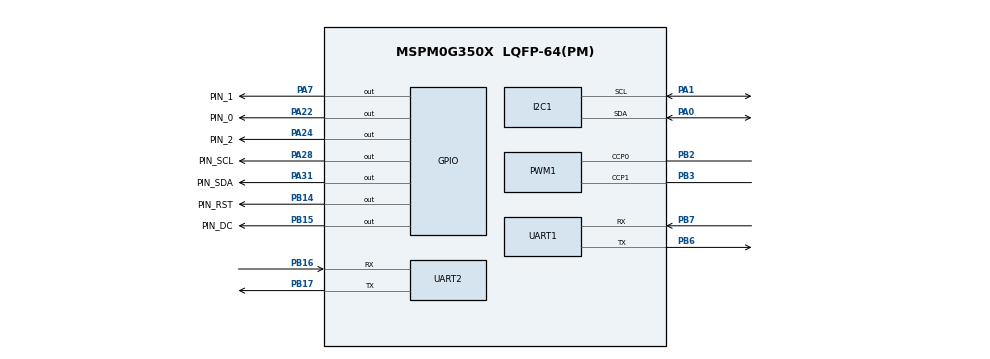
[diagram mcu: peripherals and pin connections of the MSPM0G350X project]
/**
 * These arguments were used when this file was generated. They will be automatically applied on subsequent loads
 * via the GUI or CLI. Run CLI with '--help' for additional information on how to override these arguments.
 * @cliArgs --device "MSPM0G350X" --package "LQFP-64(PM)" --part "Default" --product "mspm0_sdk@2.01.00.03"
 * @versions {"tool":"1.20.0+3587"}
 */

/**
 * Import the modules used in this configuration.
 */
const GPIO    = scripting.addModule("/ti/driverlib/GPIO", {}, false);
const GPIO1   = GPIO.addInstance();
const GPIO2   = GPIO.addInstance();
const GPIO3   = GPIO.addInstance();
const GPIO4   = GPIO.addInstance();
const GPIO5   = GPIO.addInstance();
const GPIO6   = GPIO.addInstance();
const GPIO7   = GPIO.addInstance();
const GPIO8   = GPIO.addInstance();
const GPIO9   = GPIO.addInstance();
const GPIO10  = GPIO.addInstance();
const GPIO11  = GPIO.addInstance();
const ADC12   = scripting.addModule("/ti/driverlib/ADC12", {}, false);
const ADC121  = ADC12.addInstance();
const DMA     = scripting.addModule("/ti/driverlib/DMA", {}, false);
const I2C     = scripting.addModule("/ti/driverlib/I2C", {}, false);
const I2C1    = I2C.addInstance();
const PWM     = scripting.addModule("/ti/driverlib/PWM", {}, false);
const PWM1    = PWM.addInstance();
const SYSCTL  = scripting.addModule("/ti/driverlib/SYSCTL");
const SYSTICK = scripting.addModule("/ti/driverlib/SYSTICK");
const TIMER   = scripting.addModule("/ti/driverlib/TIMER", {}, false);
const TIMER1  = TIMER.addInstance();
const UART    = scripting.addModule("/ti/driverlib/UART", {}, false);
const UART1   = UART.addInstance();
const UART2   = UART.addInstance();

/**
 * Write custom configuration values to the imported modules.
 */
const divider7       = system.clockTree["PLL_PDIV"];
divider7.divideValue = 2;

const divider9       = system.clockTree["UDIV"];
divider9.divideValue = 2;

const multiplier2         = system.clockTree["PLL_QDIV"];
multiplier2.multiplyValue = 5;

const mux8       = system.clockTree["HSCLKMUX"];
mux8.inputSelect = "HSCLKMUX_SYSPLL2X";

GPIO1.$name                         = "OLED_RST";
GPIO1.associatedPins[0].$name       = "PIN_RST";
GPIO1.associatedPins[0].pin.$assign = "PB14";

const Board = scripting.addModule("/ti/driverlib/Board", {}, false);

GPIO2.$name                         = "OLED_DC";
GPIO2.associatedPins[0].$name       = "PIN_DC";
GPIO2.associatedPins[0].pin.$assign = "PB15";

GPIO3.$name                         = "OLED_SCL";
GPIO3.associatedPins[0].$name       = "PIN_SCL";
GPIO3.associatedPins[0].pin.$assign = "PA28";

GPIO4.$name                         = "OLED_SDA";
GPIO4.associatedPins[0].$name       = "PIN_SDA";
GPIO4.associatedPins[0].pin.$assign = "PA31";

GPIO5.$name                          = "LED";
GPIO5.associatedPins[0].$name        = "led_0";
GPIO5.associatedPins[0].initialValue = "SET";
GPIO5.associatedPins[0].assignedPort = "PORTB";
GPIO5.associatedPins[0].assignedPin  = "9";

GPIO6.$name                          = "KEY";
GPIO6.associatedPins[0].$name        = "key_0";
GPIO6.associatedPins[0].direction    = "INPUT";
GPIO6.associatedPins[0].assignedPort = "PORTB";
GPIO6.associatedPins[0].assignedPin  = "8";

GPIO7.$name                          = "AIN";
GPIO7.associatedPins.create(2);
GPIO7.associatedPins[0].$name        = "AIN1";
GPIO7.associatedPins[0].assignedPort = "PORTA";
GPIO7.associatedPins[0].assignedPin  = "13";
GPIO7.associatedPins[1].$name        = "AIN2";
GPIO7.associatedPins[1].assignedPort = "PORTA";
GPIO7.associatedPins[1].assignedPin  = "14";

GPIO8.$name                          = "BIN";
GPIO8.associatedPins.create(2);
GPIO8.associatedPins[0].$name        = "BIN1";
GPIO8.associatedPins[0].assignedPort = "PORTA";
GPIO8.associatedPins[0].assignedPin  = "17";
GPIO8.associatedPins[1].$name        = "BIN2";
GPIO8.associatedPins[1].assignedPort = "PORTA";
GPIO8.associatedPins[1].assignedPin  = "16";

GPIO9.$name                               = "ENCODERA";
GPIO9.associatedPins.create(2);
GPIO9.associatedPins[0].direction         = "INPUT";
GPIO9.associatedPins[0].assignedPort      = "PORTA";
GPIO9.associatedPins[0].assignedPin       = "25";
GPIO9.associatedPins[0].interruptEn       = true;
GPIO9.associatedPins[0].interruptPriority = "0";
GPIO9.associatedPins[0].polarity          = "RISE";
GPIO9.associatedPins[0].$name             = "E1A";
GPIO9.associatedPins[1].direction         = "INPUT";
GPIO9.associatedPins[1].assignedPort      = "PORTA";
GPIO9.associatedPins[1].assignedPin       = "26";
GPIO9.associatedPins[1].interruptEn       = true;
GPIO9.associatedPins[1].interruptPriority = "0";
GPIO9.associatedPins[1].polarity          = "RISE";
GPIO9.associatedPins[1].$name             = "E1B";

GPIO10.$name                               = "ENCODERB";
GPIO10.associatedPins.create(2);
GPIO10.associatedPins[0].direction         = "INPUT";
GPIO10.associatedPins[0].assignedPort      = "PORTB";
GPIO10.associatedPins[0].assignedPin       = "20";
GPIO10.associatedPins[0].interruptEn       = true;
GPIO10.associatedPins[0].interruptPriority = "0";
GPIO10.associatedPins[0].polarity          = "RISE";
GPIO10.associatedPins[0].$name             = "E2A";
GPIO10.associatedPins[1].direction         = "INPUT";
GPIO10.associatedPins[1].assignedPort      = "PORTB";
GPIO10.associatedPins[1].assignedPin       = "24";
GPIO10.associatedPins[1].interruptEn       = true;
GPIO10.associatedPins[1].polarity          = "RISE";
GPIO10.associatedPins[1].interruptPriority = "0";
GPIO10.associatedPins[1].$name             = "E2B";

/* ── ADC+DMA 灰度传感器（CD4051 8:1 mux, PA27=ADC输入） ── */
ADC121.$name                             = "ADC12_0";
ADC121.sampleTime0                       = "2 us";
ADC121.sampClkDiv                        = "DL_ADC12_CLOCK_DIVIDE_8";
ADC121.adcMem0_name                      = "ADC_CH0";
ADC121.repeatMode                        = true;
ADC121.configureDMA                      = true;
ADC121.sampClkSrc                        = "DL_ADC12_CLOCK_ULPCLK";
ADC121.sampCnt                           = 1;
ADC121.enabledDMATriggers                = ["DL_ADC12_DMA_MEM0_RESULT_LOADED"];
ADC121.peripheral.$assign                = "ADC0";
ADC121.peripheral.adcPin0.$assign        = "PA27";
ADC121.DMA_CHANNEL.$name                 = "DMA_CH0";
ADC121.DMA_CHANNEL.srcLength             = "HALF_WORD";
ADC121.DMA_CHANNEL.dstLength             = "HALF_WORD";
ADC121.DMA_CHANNEL.addressMode           = "f2b";
ADC121.DMA_CHANNEL.configureTransferSize = true;
ADC121.DMA_CHANNEL.transferSize          = 40;
ADC121.DMA_CHANNEL.transferMode          = "FULL_CH_REPEAT_SINGLE";

/* ── CD4051 地址线 GPIO ── */
GPIO11.$name                         = "Gray_Address";
GPIO11.associatedPins.create(3);
GPIO11.associatedPins[0].$name       = "PIN_0";
GPIO11.associatedPins[0].pin.$assign = "PA22";
GPIO11.associatedPins[1].$name       = "PIN_1";
GPIO11.associatedPins[1].pin.$assign = "PA7";
GPIO11.associatedPins[2].$name       = "PIN_2";
GPIO11.associatedPins[2].pin.$assign = "PA24";

/* ── I2C0: BMI088 IMU (PA0=SDA, PA1=SCL) ── */
I2C1.$name                      = "I2C_0";
I2C1.peripheral.$assign         = "I2C0";
I2C1.peripheral.sdaPin.$assign  = "PA0";
I2C1.peripheral.sclPin.$assign  = "PA1";
I2C1.basicEnableController       = true;
I2C1.basicControllerStandardBusSpeed = "Standard";

PWM1.$name                      = "PWM_0";
PWM1.pwmMode                    = "EDGE_ALIGN_UP";
PWM1.timerStartTimer            = true;
PWM1.timerCount                 = 2000;
PWM1.clockPrescale              = 4;
PWM1.peripheral.$assign         = "TIMG6";
PWM1.peripheral.ccp0Pin.$assign = "PB2";
PWM1.peripheral.ccp1Pin.$assign = "PB3";
PWM1.PWM_CHANNEL_0.$name        = "ti_driverlib_pwm_PWMTimerCC0";
PWM1.PWM_CHANNEL_0.initVal      = "HIGH";
PWM1.PWM_CHANNEL_1.$name        = "ti_driverlib_pwm_PWMTimerCC1";
PWM1.PWM_CHANNEL_1.initVal      = "HIGH";

SYSCTL.forceDefaultClkConfig = true;
SYSCTL.clockTreeEn           = true;

SYSTICK.periodEnable  = true;
SYSTICK.systickEnable = true;
SYSTICK.period        = 16777216;

TIMER1.$name              = "TIMER_0";
TIMER1.timerMode          = "PERIODIC_UP";
TIMER1.interrupts         = ["LOAD"];
TIMER1.timerClkPrescale   = 256;
TIMER1.timerStartTimer    = true;
TIMER1.timerPeriod        = "0.01";
TIMER1.interruptPriority  = "2";
TIMER1.peripheral.$assign = "TIMG0";

/* ── UART1: 蓝牙串口 (PB6=TX, PB7=RX) ── */
UART1.$name                            = "UART_1";
UART1.peripheral.$assign               = "UART1";
UART1.peripheral.rxPin.$assign         = "PB7";
UART1.peripheral.txPin.$assign         = "PB6";

/* ── UART2: 备用串口 (PB16=RX, PB17=TX) ── */
UART2.$name                            = "UART_2";
UART2.peripheral.$assign               = "UART2";
UART2.peripheral.rxPin.$assign         = "PB16";
UART2.peripheral.txPin.$assign         = "PB17";

/**
 * Pinmux solution for unlocked pins/peripherals. This ensures that minor changes to the automatic solver in a future
 * version of the tool will not impact the pinmux you originally saw.  These lines can be completely deleted in order to
 * re-solve from scratch.
 */
Board.peripheral.$suggestSolution             = "DEBUGSS";
Board.peripheral.swclkPin.$suggestSolution    = "PA20";
Board.peripheral.swdioPin.$suggestSolution    = "PA19";
GPIO5.associatedPins[0].pin.$suggestSolution  = "PB9";
GPIO6.associatedPins[0].pin.$suggestSolution  = "PB8";
GPIO7.associatedPins[0].pin.$suggestSolution  = "PA13";
GPIO7.associatedPins[1].pin.$suggestSolution  = "PA14";
GPIO8.associatedPins[0].pin.$suggestSolution  = "PA17";
GPIO8.associatedPins[1].pin.$suggestSolution  = "PA16";
GPIO9.associatedPins[0].pin.$suggestSolution  = "PA25";
GPIO9.associatedPins[1].pin.$suggestSolution  = "PA26";
GPIO10.associatedPins[0].pin.$suggestSolution = "PB20";
GPIO10.associatedPins[1].pin.$suggestSolution = "PB24";
GPIO11.associatedPins[0].pin.$suggestSolution  = "PA22";
GPIO11.associatedPins[1].pin.$suggestSolution  = "PA7";
GPIO11.associatedPins[2].pin.$suggestSolution  = "PA24";
ADC121.DMA_CHANNEL.peripheral.$suggestSolution = "DMA_CH0";
